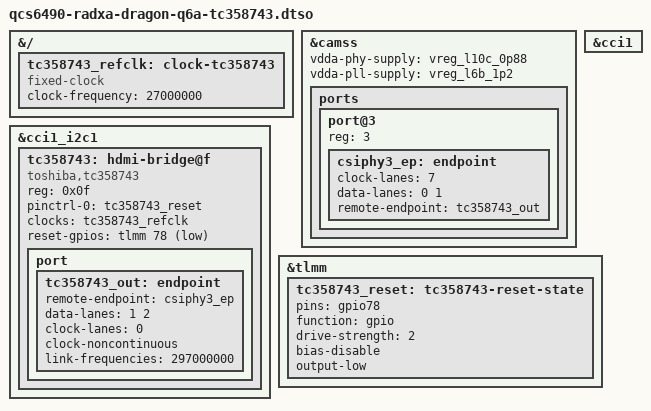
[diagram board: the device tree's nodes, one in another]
// SPDX-License-Identifier: BSD-3-Clause
/*
 * Copyright (c) 2026 Radxa Computer (Shenzhen) Co., Ltd.
 */

/dts-v1/;
/plugin/;

#include <dt-bindings/gpio/gpio.h>

&{/} {
	tc358743_refclk: clock-tc358743 {
		compatible = "fixed-clock";
		#clock-cells = <0>;
		clock-frequency = <27000000>;
	};
};

&camss {
	vdda-phy-supply = <&vreg_l10c_0p88>;
	vdda-pll-supply = <&vreg_l6b_1p2>;

	status = "okay";

	ports {
		#address-cells = <1>;
		#size-cells = <0>;

		/* csiphy3 */
		port@3 {
			reg = <3>;

			csiphy3_ep: endpoint {
				clock-lanes = <7>;
				data-lanes = <0 1>;
				remote-endpoint = <&tc358743_out>;
			};
		};
	};
};

&cci1 {
	status = "okay";
};

&cci1_i2c1 {
	#address-cells = <1>;
	#size-cells = <0>;

	tc358743: hdmi-bridge@f {
		compatible = "toshiba,tc358743";
		reg = <0x0f>;

		pinctrl-names = "default";
		pinctrl-0 = <&tc358743_reset>;

		clocks = <&tc358743_refclk>;
		clock-names = "refclk";

		reset-gpios = <&tlmm 78 GPIO_ACTIVE_LOW>;

		port {
			tc358743_out: endpoint {
				remote-endpoint = <&csiphy3_ep>;
				data-lanes = <1 2>;
				clock-lanes = <0>;
				clock-noncontinuous;
				link-frequencies = /bits/ 64 <297000000>;
			};
		};
	};
};

&tlmm {
	tc358743_reset: tc358743-reset-state {
		pins = "gpio78";
		function = "gpio";
		drive-strength = <2>;
		bias-disable;
		output-low;
	};
};
